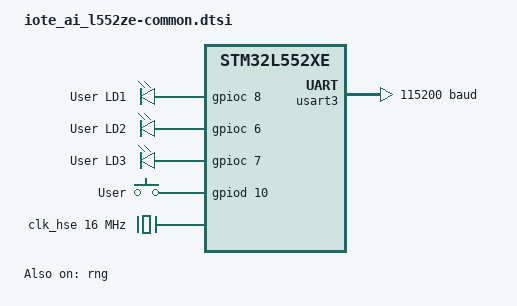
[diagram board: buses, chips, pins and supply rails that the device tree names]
/*
 * Copyright (c) 2020 Petri Oksanen
 *
 * SPDX-License-Identifier: Apache-2.0
 */

 #include <st/l5/stm32l552Xe.dtsi>
 #include <st/l5/stm32l552z(c-e)txq-pinctrl.dtsi>
 
/* 0x4000D400UL usb */

 / {
     leds {
         compatible = "gpio-leds";
         green_led_1: led_1 {
             gpios = <&gpioc 8 GPIO_ACTIVE_HIGH>;
             label = "User LD1";
         };
         blue_led_1: led_2 {
             gpios = <&gpioc 6 GPIO_ACTIVE_HIGH>;
             label = "User LD2";
         };
         red_led_1: led_3 {
             gpios = <&gpioc 7 GPIO_ACTIVE_HIGH>;
             label = "User LD3";
         };
     };
 
     gpio_keys {
         compatible = "gpio-keys";
         user_button: button {
             label = "User";
             gpios = <&gpiod 10 GPIO_ACTIVE_HIGH>;
         };
     };

     power-states {
		stop0: state0 {
			compatible = "zephyr,power-state";
			power-state-name = "suspend-to-idle";
			substate-id = <1>;
			min-residency-us = <100>;
		};
		stop1: state1 {
			compatible = "zephyr,power-state";
			power-state-name = "suspend-to-idle";
			substate-id = <2>;
			min-residency-us = <500>;
		};
		stop2: state2 {
			compatible = "zephyr,power-state";
			power-state-name = "suspend-to-idle";
			substate-id = <3>;
			min-residency-us = <900>;
		};
	};
 };
  
 &clk_hse {
	clock-frequency = <DT_FREQ_M(16)>;
	status = "okay";
};

 &pll {
     div-m = <4>;
     mul-n = <55>;
     div-p = <7>;
     div-q = <8>;
     div-r = <2>;
     clocks = <&clk_hse>;
     status = "okay";
 };
 
 &rcc {
     clocks = <&pll>;
     clock-frequency = <DT_FREQ_M(110)>;
     ahb-prescaler = <1>;
     apb1-prescaler = <1>;
     apb2-prescaler = <1>;
 };
 
 &clk_lse {
	status = "okay";
};

 &rng {
     status = "okay";
 };
 
 &usart3 {
    current-speed = <115200>;
    status = "okay";
};

/* 
&spi1 {
	pinctrl-0 = <&spi1_sck_pg2 &spi1_miso_pg3 &spi1_mosi_pg4>;
	status = "okay";
	cs-gpios = <&gpiog 5 GPIO_ACTIVE_LOW>;
	w25q128jvs: w25q128jvs@0 {
		compatible = "jedec,spi-nor";
		label = "W25Q128JVS";
		reg = <0>;
		spi-max-frequency = <40000000>;
		size = <0x1000000>;
		has-dpd;
		t-enter-dpd = <4000>;
		t-exit-dpd = <25000>;
		jedec-id = [ef 40 15];
	};
};
*/

